# Template register map
Vendor: VendorName Co.Ltd; Series: SeriesName; File version: 1.2
CPU: CM7 r0p1, little endian, MPU, FPU, 4 interrupt priority bits
Registers are 32-bit, read-write, no defined reset value unless marked. A register's access mark holds for its fields unless they carry their own. Offsets are from the block's base; [hi:lo] are bit positions; lines under a group give offsets from that group; {n}, {i} and the like mark numbered series.

## ECAP1 — Enhanced Capture 1
Base 0x4001D000
Same registers: ECAP2 0x4001D200, ECAP3 0x4001D400, ECAP4 0x4001D600, ECAP5 0x4001D800, ECAP6 0x4001DA00, ECAP7 0x4001DC00
0x00 TSCTR ro — ECAP timestamp control register
  [31:0] TSCTR — ECAP TSCTR[31:0] bit: active 32-bit counter register that is used as the capture time-base HR mode
0x04 CTRPHS — ECAP phase control register
  [31:0] CTRPHS — ECAP CTRPHS[31:0] bit: counter phase value register that can be programmed for phase lag or lead
{0x4+4i} CAP{i} (i=1..4) — ECAP capture {i} register
  [31:0] CAP{i} — ECAP CAP{i}[31:0] bit: time-stamp capture register {i}
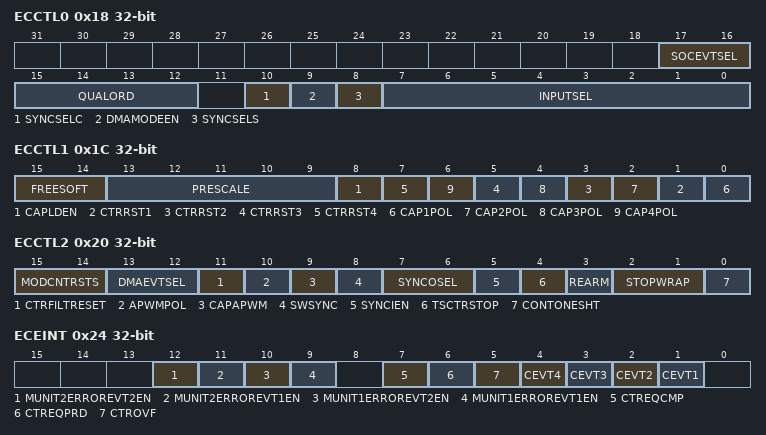
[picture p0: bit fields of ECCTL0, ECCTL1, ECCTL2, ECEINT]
0x18 ECCTL0 — ECAP event capture control register
  [17:16] SOCEVTSEL — ECAP SOCEVTSEL[1:0] bit: source event select
  [15:12] QUALORD — ECAP QUALORD[3:0] bit: quantity load
  [10] SYNCSELC — ECAP SYNCSELC bit: sync select control
  [9] DMAMODEEN — ECAP DMAMODEEN bit: DMA mode enable
  [8] SYNCSELS — ECAP SYNCSELS bit: sync select set
  [7:0] INPUTSEL — ECAP INPUTSEL[7:0] bit: capture input source select bits
0x1C ECCTL1 — ECAP control register 1
  [15:14] FREESOFT — ECAP FREESOFT[1:0] bit: emulation control
  [13:9] PRESCALE — ECAP PRESCALE[4:0] bit: event filter prescale select
  [8] CAPLDEN — ECAP CAPLDEN bit: enable loading of CAP1-4 registers on a capture event
  [2n-1] CTRRST{n} (n=1..4) — ECAP CTRRST{n} bit: counter reset on capture event {n}
  [2n-2] CAP{n}POL (n=1..4) — ECAP CAP{n}POL bit: capture event {n} polarity select
0x20 ECCTL2 — ECAP control register 2
  [15:14] MODCNTRSTS — ECAP MODCNTRSTS[1:0] bit: this bit field reads current status on modulo counter
  [13:12] DMAEVTSEL — ECAP DMAEVTSEL[1:0] bit: DMA event select
  [11] CTRFILTRESET — ECAP CTRFILTRESET bit: reset bit
  [10] APWMPOL — ECAP APWMPOL bit: APWM output polarity select
  [9] CAPAPWM — ECAP CAPAPWM bit: CAP or APWM operating mode select
  [8] SWSYNC — ECAP SWSYNC bit: Software-forced counter synchronizer
  [7:6] SYNCOSEL — ECAP SYNCOSEL[1:0] bit: sync-out select
  [5] SYNCIEN — ECAP SYNCIEN bit: counter sync-in select mode
  [4] TSCTRSTOP — ECAP TSCTRSTOP bit: time stamp counter stop control
  [3] REARM — ECAP REARM bit: re-arming control
  [2:1] STOPWRAP — ECAP STOPWRAP[1:0] bit: stop value for one-shot mode
  [0] CONTONESHT — ECAP CONTONESHT bit: continuous or one-shot mode control
0x24 ECEINT — ECAP interrupt enable register
  [12] MUNIT2ERROREVT2EN — ECAP MUNIT2ERROREVT2EN bit: monitor unit 2 error event 2 enable
  [11] MUNIT2ERROREVT1EN — ECAP MUNIT2ERROREVT1EN bit: monitor unit 2 error event 1 enable
  [10] MUNIT1ERROREVT2EN — ECAP MUNIT1ERROREVT2EN bit: monitor unit 1 error event 2 enable
  [9] MUNIT1ERROREVT1EN — ECAP MUNIT1ERROREVT1EN bit: monitor unit 1 error event 1 enable
  [7] CTREQCMP — ECAP CTREQCMP bit: counter equal compare interrupt enable
  [6] CTREQPRD — ECAP CTREQPRD bit: counter equal period interrupt enable
  [5] CTROVF — ECAP CTROVF bit: counter overflow interrupt enable
  [n] CEVT{n} (n=1..4) — ECAP CEVT{n} bit: capture event {n} interrupt enable
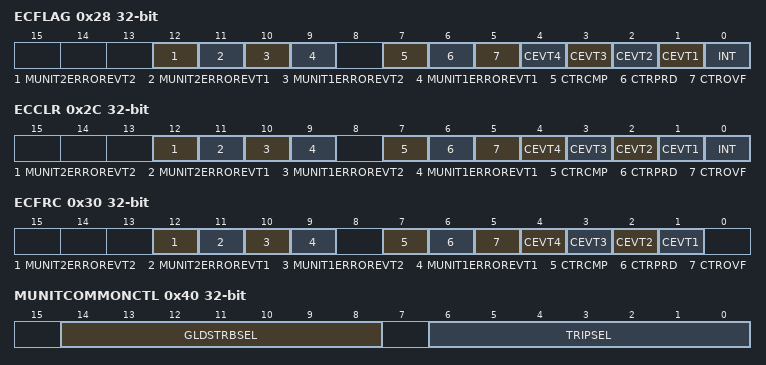
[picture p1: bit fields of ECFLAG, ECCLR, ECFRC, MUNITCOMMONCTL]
0x28 ECFLAG ro — ECAP interrupt flag register
  [12] MUNIT2ERROREVT2 — ECAP MUNIT2ERROREVT2 bit: monitor unit 2 error event 2 interrupt flag
  [11] MUNIT2ERROREVT1 — ECAP MUNIT2ERROREVT1 bit: monitor unit 2 error event 1 interrupt flag
  [10] MUNIT1ERROREVT2 — ECAP MUNIT1ERROREVT2 bit: monitor unit 1 error event 2 interrupt flag
  [9] MUNIT1ERROREVT1 — ECAP MUNIT1ERROREVT1 bit: monitor unit 1 error event 1 interrupt flag
  [7] CTRCMP — ECAP CTRCMP bit: compare equal compare status flag
  [6] CTRPRD — ECAP CTRPRD bit: counter equal period status flag
  [5] CTROVF — ECAP CTROVF bit: counter overflow status flag
  [4] CEVT4 — ECAP CEVT4 bit: capture event 4 status flag
  [3] CEVT3 — ECAP CEVT3 bit: capture event 3 status flag
  [2] CEVT2 — ECAP CEVT2 bit: capture event 2 status flagc
  [1] CEVT1 — ECAP CEVT1 bit: capture event 1 status flag
  [0] INT — ECAP INT bit: global interrupt status flag
0x2C ECCLR — ECAP interrupt flag clear register
  [12] MUNIT2ERROREVT2 — ECAP MUNIT2ERROREVT2 bit: monitor unit 2 error event 2 interrupt flag clear
  [11] MUNIT2ERROREVT1 — ECAP MUNIT2ERROREVT1 bit: monitor unit 2 error event 1 interrupt flag clear
  [10] MUNIT1ERROREVT2 — ECAP MUNIT1ERROREVT2 bit: monitor unit 1 error event 2 interrupt flag clear
  [9] MUNIT1ERROREVT1 — ECAP MUNIT1ERROREVT1 bit: monitor unit 1 error event 1 interrupt flag clear
  [7] CTRCMP — ECAP CTRCMP bit: counter equal compare status clear
  [6] CTRPRD — ECAP CTRPRD bit: counter equal period status clear
  [5] CTROVF — ECAP CTROVF bit: counter overflow status clear
  [n] CEVT{n} (n=1..4) — ECAP CEVT{n} bit: capture event {n} status clear
  [0] INT — ECAP INT bit: ECAP global interrupt status clear
0x30 ECFRC — ECAP software interrupt register
  [12] MUNIT2ERROREVT2 — ECAP MUNIT2ERROREVT2 bit: monitor unit 2 error event 2 interrupt software generate
  [11] MUNIT2ERROREVT1 — ECAP MUNIT2ERROREVT1 bit: monitor unit 2 error event 1 interrupt software generate
  [10] MUNIT1ERROREVT2 — ECAP MUNIT1ERROREVT2 bit: monitor unit 1 error event 2 interrupt software generate
  [9] MUNIT1ERROREVT1 — ECAP MUNIT1ERROREVT1 bit: monitor unit 1 error event 1 interrupt software generate
  [7] CTRCMP — ECAP CTRCMP bit: force counter equal compare interrupt
  [6] CTRPRD — ECAP CTRPRD bit: force counter equal period interrupt
  [5] CTROVF — ECAP CTROVF bit: force counter overflow
  [n] CEVT{n} (n=1..4) — ECAP CEVT{n} bit: force capture event {n}
0x34 ECAPSYNCINSEL — ECAP synchronization pulse selection register
  [4:0] SEL — ECAP SEL[4:0] bit: these bits determines the source of SYNCIN signal
0x40 MUNITCOMMONCTL — ECAP monitor unit common control register
  [14:8] GLDSTRBSEL — ECAP GLDSTRBSEL[6:0] bit: global loading selection signal select
  [6:0] TRIPSEL — ECAP TRIPSEL[6:0] bit: trip signal select
{0x44+0x20*i} MUNITXGRP[{i}] (i=0..1) group — Grouping of MUNIT1~MUNIT2
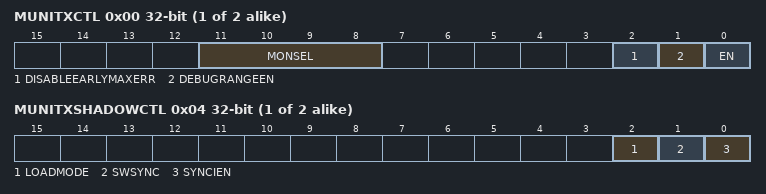
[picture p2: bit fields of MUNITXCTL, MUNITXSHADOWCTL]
  0x00 MUNITXCTL — ECAP monitor unit x control register
    [11:8] MONSEL — ECAP MONSEL[3:0] bit: monitor mode select x
    [2] DISABLEEARLYMAXERR — ECAP DISABLEEARLYMAXERR bit: disable early maximum error check x
    [1] DEBUGRANGEEN — ECAP DEBUGRANGEEN bit: debug range enable x
    [0] EN — ECAP EN bit: monitor unit enable x
  0x04 MUNITXSHADOWCTL — ECAP monitor unit x shadow control register
    [2] LOADMODE — ECAP LOADMODE bit: load mode x
    [1] SWSYNC — ECAP SWSYNC bit: software synchronization x
    [0] SYNCIEN — ECAP SYNCIEN bit: shadow register enable
  0x08 MUNITXMIN — ECAP monitor unit x min register
    [31:0] MINVALUE — ECAP MINVALUE[31:0] bit: monitor unit minimum value x
  0x0C MUNITXMAX — ECAP monitor unit x max register
    [31:0] MAXVALUE — ECAP MAXVALUE[31:0] bit: monitor unit maximum value x
  0x10 MUNITXMINSHADOW — ECAP monitor unit x min shadow register
    [31:0] MINVALUESHADOW — ECAP MINVALUESHADOW[31:0] bit: minimum value of shadow for monitor
  0x14 MUNITXMAXSHADOW — ECAP monitor unit x max shadow register
    [31:0] MAXVALUESHADOW — ECAP MAXVALUESHADOW[31:0] bit: maximum value of shadow for monitor
  0x18 MUNITXDEBUGRANGEMIN ro — ECAP monitor unit x min debug range register
    [31:0] MINVALUE — ECAP MINVALUE[31:0] bit: observed minimum value x
  0x1C MUNITXDEBUGRANGEMAX ro — ECAP monitor unit x max debug range register
    [31:0] MAXVALUE — ECAP MAXVALUE[31:0] bit: observed maximum value x
